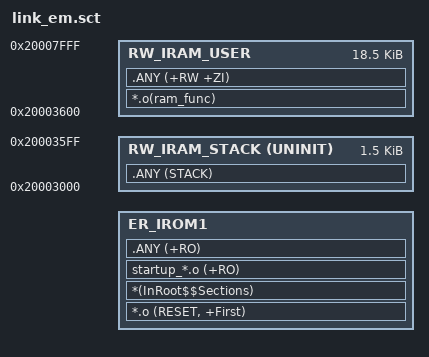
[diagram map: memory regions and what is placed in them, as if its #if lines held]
#! armcc -E --preinclude=..\src\cfg.h

#define SCT_EM_BASE       (0x20008000)

#if (SCT_EM_STEP)
    #define SCT_EM        (SCT_EM_BASE + (0x200 * SCT_EM_STEP))
#else
    #define SCT_EM        (SCT_EM_BASE)
#endif
    
#define SCT_EM_LEN        (0x2000A000 - SCT_EM)

LR_IROM1 SCT_EM SCT_EM_LEN  
{
    ER_IROM1 +0
    {
        *.o (RESET, +First)
        *(InRoot$$Sections)
        startup_*.o (+RO)
        .ANY (+RO)
    }
    
    RW_IRAM_USER 0x20003600 0x4A00
    {
        *.o(ram_func)
        .ANY (+RW +ZI)
    }

    RW_IRAM_STACK 0x20003600-0x600 UNINIT 0x600
    {
        .ANY (STACK)
    }
}
